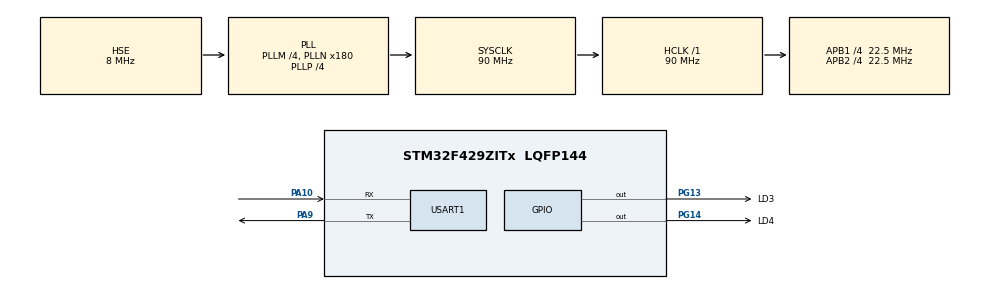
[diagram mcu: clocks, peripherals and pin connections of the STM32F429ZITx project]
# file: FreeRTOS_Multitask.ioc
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FREERTOS.Tasks01=defaultTask,24,128,StartDefaultTask,Default,NULL,Dynamic,NULL,NULL;myTask,24,128,StartMyTask,Default,NULL,Dynamic,NULL,NULL;myLowTask,8,128,StartLowTask,Default,NULL,Dynamic,NULL,NULL
Mcu.Family=STM32F4
Mcu.Name=STM32F429ZITx
Mcu.Package=LQFP144
NVIC.PriorityGroup=NVIC_PRIORITYGROUP_4
PA10.Mode=Asynchronous
PA10.Signal=USART1_RX
PA9.Mode=Asynchronous
PA9.Signal=USART1_TX
PG13.GPIO_Label=LD3
PG13.Signal=GPIO_Output
PG14.GPIO_Label=LD4
PG14.Signal=GPIO_Output
PH0/OSC_IN.Mode=HSE-External-Oscillator
PH0/OSC_IN.Signal=RCC_OSC_IN
PH1/OSC_OUT.Mode=HSE-External-Oscillator
PH1/OSC_OUT.Signal=RCC_OSC_OUT
ProjectManager.HeapSize=0x200
ProjectManager.StackSize=0x400
ProjectManager.TargetToolchain=STM32CubeIDE
RCC.48MHZClocksFreq_Value=90000000
RCC.AHBFreq_Value=90000000
RCC.APB1CLKDivider=RCC_HCLK_DIV4
RCC.APB1Freq_Value=22500000
RCC.APB1TimFreq_Value=45000000
RCC.APB2CLKDivider=RCC_HCLK_DIV4
RCC.APB2Freq_Value=22500000
RCC.APB2TimFreq_Value=45000000
RCC.CortexFreq_Value=90000000
RCC.HCLKFreq_Value=90000000
RCC.HSE_VALUE=8000000
RCC.HSI_VALUE=16000000
RCC.LSE_VALUE=32768
RCC.PLLM=4
RCC.PLLN=180
RCC.PLLP=RCC_PLLP_DIV4
RCC.PLLSourceVirtual=RCC_PLLSOURCE_HSE
RCC.SYSCLKFreq_VALUE=90000000
RCC.SYSCLKSource=RCC_SYSCLKSOURCE_PLLCLK
RCC.VCOOutputFreq_Value=360000000
TIM6.Period=99
TIM6.Prescaler=89
USART1.VirtualMode=VM_ASYNC
VP_FREERTOS_VS_CMSIS_V2.Mode=CMSIS_V2
VP_TIM6_VS_ClockSourceINT.Mode=Enable_Timer
board=custom

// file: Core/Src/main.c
/* USER CODE BEGIN Header */
/**
  ******************************************************************************
  * @file           : main.c
  * @brief          : Main program body
  ******************************************************************************
  * @attention
  *
  * Copyright (c) 2025 STMicroelectronics.
  * All rights reserved.
  *
  * This software is licensed under terms that can be found in the LICENSE file
  * in the root directory of this software component.
  * If no LICENSE file comes with this software, it is provided AS-IS.
  *
  ******************************************************************************
  */
/* USER CODE END Header */
#include "main.h"
#include "cmsis_os.h"

TIM_HandleTypeDef htim6;

UART_HandleTypeDef huart1;

/* Definitions for defaultTask */
osThreadId_t defaultTaskHandle;
const osThreadAttr_t defaultTask_attributes = {
  .name = "defaultTask",
  .stack_size = 128 * 4,
  .priority = (osPriority_t) osPriorityNormal,
};
/* Definitions for myTask */
osThreadId_t myTaskHandle;
const osThreadAttr_t myTask_attributes = {
  .name = "myTask",
  .stack_size = 128 * 4,
  .priority = (osPriority_t) osPriorityNormal,
};
/* Definitions for myLowTask */
osThreadId_t myLowTaskHandle;
const osThreadAttr_t myLowTask_attributes = {
  .name = "myLowTask",
  .stack_size = 128 * 4,
  .priority = (osPriority_t) osPriorityLow,
};

void SystemClock_Config(void);
static void MX_GPIO_Init(void);
static void MX_USART1_UART_Init(void);
static void MX_TIM6_Init(void);
void StartDefaultTask(void *argument);
void StartMyTask(void *argument);
void StartLowTask(void *argument);

int main(void)
{

  /* MCU Configuration--------------------------------------------------------*/

  /* Reset of all peripherals, Initializes the Flash interface and the Systick. */
  HAL_Init();

  /* Configure the system clock */
  SystemClock_Config();

  /* Initialize all configured peripherals */
  MX_GPIO_Init();
  MX_USART1_UART_Init();
  MX_TIM6_Init();

  /* Init scheduler */
  osKernelInitialize();

  /* Create the thread(s) */
  /* creation of defaultTask */
  defaultTaskHandle = osThreadNew(StartDefaultTask, NULL, &defaultTask_attributes);

  /* creation of myTask */
  myTaskHandle = osThreadNew(StartMyTask, NULL, &myTask_attributes);

  /* creation of myLowTask */
  myLowTaskHandle = osThreadNew(StartLowTask, NULL, &myLowTask_attributes);

  /* Start scheduler */
  osKernelStart();

  /* We should never get here as control is now taken by the scheduler */

  /* Infinite loop */
  while (1)
  {

  }
}

void SystemClock_Config(void)
{
  RCC_OscInitTypeDef RCC_OscInitStruct = {0};
  RCC_ClkInitTypeDef RCC_ClkInitStruct = {0};

  /** Configure the main internal regulator output voltage
  */
  __HAL_RCC_PWR_CLK_ENABLE();
  __HAL_PWR_VOLTAGESCALING_CONFIG(PWR_REGULATOR_VOLTAGE_SCALE3);

  /** Initializes the RCC Oscillators according to the specified parameters
  * in the RCC_OscInitTypeDef structure.
  */
  RCC_OscInitStruct.OscillatorType = RCC_OSCILLATORTYPE_HSE;
  RCC_OscInitStruct.HSEState = RCC_HSE_ON;
  RCC_OscInitStruct.PLL.PLLState = RCC_PLL_ON;
  RCC_OscInitStruct.PLL.PLLSource = RCC_PLLSOURCE_HSE;
  RCC_OscInitStruct.PLL.PLLM = 4;
  RCC_OscInitStruct.PLL.PLLN = 180;
  RCC_OscInitStruct.PLL.PLLP = RCC_PLLP_DIV4;
  RCC_OscInitStruct.PLL.PLLQ = 4;
  if (HAL_RCC_OscConfig(&RCC_OscInitStruct) != HAL_OK)
  {
    Error_Handler();
  }

  /** Initializes the CPU, AHB and APB buses clocks
  */
  RCC_ClkInitStruct.ClockType = RCC_CLOCKTYPE_HCLK|RCC_CLOCKTYPE_SYSCLK
                              |RCC_CLOCKTYPE_PCLK1|RCC_CLOCKTYPE_PCLK2;
  RCC_ClkInitStruct.SYSCLKSource = RCC_SYSCLKSOURCE_PLLCLK;
  RCC_ClkInitStruct.AHBCLKDivider = RCC_SYSCLK_DIV1;
  RCC_ClkInitStruct.APB1CLKDivider = RCC_HCLK_DIV4;
  RCC_ClkInitStruct.APB2CLKDivider = RCC_HCLK_DIV4;

  if (HAL_RCC_ClockConfig(&RCC_ClkInitStruct, FLASH_LATENCY_2) != HAL_OK)
  {
    Error_Handler();
  }
}

static void MX_TIM6_Init(void)
{

  TIM_MasterConfigTypeDef sMasterConfig = {0};

  htim6.Instance = TIM6;
  htim6.Init.Prescaler = 89;
  htim6.Init.CounterMode = TIM_COUNTERMODE_UP;
  htim6.Init.Period = 99;
  htim6.Init.AutoReloadPreload = TIM_AUTORELOAD_PRELOAD_DISABLE;
  if (HAL_TIM_Base_Init(&htim6) != HAL_OK)
  {
    Error_Handler();
  }
  sMasterConfig.MasterOutputTrigger = TIM_TRGO_RESET;
  sMasterConfig.MasterSlaveMode = TIM_MASTERSLAVEMODE_DISABLE;
  if (HAL_TIMEx_MasterConfigSynchronization(&htim6, &sMasterConfig) != HAL_OK)
  {
    Error_Handler();
  }

}

static void MX_USART1_UART_Init(void)
{

  huart1.Instance = USART1;
  huart1.Init.BaudRate = 115200;
  huart1.Init.WordLength = UART_WORDLENGTH_8B;
  huart1.Init.StopBits = UART_STOPBITS_1;
  huart1.Init.Parity = UART_PARITY_NONE;
  huart1.Init.Mode = UART_MODE_TX_RX;
  huart1.Init.HwFlowCtl = UART_HWCONTROL_NONE;
  huart1.Init.OverSampling = UART_OVERSAMPLING_16;
  if (HAL_UART_Init(&huart1) != HAL_OK)
  {
    Error_Handler();
  }

}

static void MX_GPIO_Init(void)
{
  GPIO_InitTypeDef GPIO_InitStruct = {0};

  /* GPIO Ports Clock Enable */
  __HAL_RCC_GPIOH_CLK_ENABLE();
  __HAL_RCC_GPIOA_CLK_ENABLE();
  __HAL_RCC_GPIOG_CLK_ENABLE();

  /*Configure GPIO pin Output Level */
  HAL_GPIO_WritePin(GPIOG, LD3_Pin|LD4_Pin, GPIO_PIN_RESET);

  /*Configure GPIO pins : LD3_Pin LD4_Pin */
  GPIO_InitStruct.Pin = LD3_Pin|LD4_Pin;
  GPIO_InitStruct.Mode = GPIO_MODE_OUTPUT_PP;
  GPIO_InitStruct.Pull = GPIO_NOPULL;
  GPIO_InitStruct.Speed = GPIO_SPEED_FREQ_LOW;
  HAL_GPIO_Init(GPIOG, &GPIO_InitStruct);

}

/* USER CODE BEGIN Header_StartDefaultTask */
/**
  * @brief  Hàm thực thi trong task mặc định của FreeRTOS, defaultTask thread.
  * @param  argument: Not used
  * @retval None
  */
/* USER CODE END Header_StartDefaultTask */
void StartDefaultTask(void *argument)
{
  /* USER CODE BEGIN 5 */
  /* Infinite loop */
  for(;;)
  {
	/// Tạm dừng 0.5s. Lưu ý: Bắt buộc phải có, cho dù thời gian đợi nhỏ
    osDelay(500);
    /// Đảo trạng thái Tắt/Bật đèn led LD3
    HAL_GPIO_TogglePin(LD3_GPIO_Port, LD3_Pin);
  }
  /* USER CODE END 5 */
}

/* USER CODE BEGIN Header_StartMyTask */
/**
* @brief Hàm thực thi bên trong Task mới, myTask thread.
* @param argument: Not used
* @retval None
*/
/* USER CODE END Header_StartMyTask */
void StartMyTask(void *argument)
{
  /* USER CODE BEGIN StartMyTask */
  /* Infinite loop */
  for(;;)
  {
	/// Tạm dừng 0.7s. Lưu ý: Bắt buộc phải có, cho dù thời gian đợi nhỏ
    //osDelay(700);   // Hàm delay none-blocking
	HAL_Delay(700);   // Hàm delay blocking, nên mới chiếm tài nguyên CPU, không để cho LowTask được thực thi
    /// Đảo trạng thái Tắt/Bật đèn led L4;
    HAL_GPIO_TogglePin(LD4_GPIO_Port, LD4_Pin);
    /// Gửi thông báo về máy tính qua UART1
    HAL_UART_Transmit(&huart1, "MyTask\n",7,10);
  }
  /* USER CODE END StartMyTask */
}

void StartLowTask(void *argument)
{
  /* USER CODE BEGIN StartLowTask */
  /* Infinite loop */
  for(;;)
  {
	/// Tạm dừng 0.7s. Lưu ý: Bắt buộc phải có, cho dù thời gian đợi nhỏ
	osDelay(700);
	/// Gửi thông báo về máy tính qua UART1
	HAL_UART_Transmit(&huart1, "LowTask\n",8,10);
  }
  /* USER CODE END StartLowTask */
}

void Error_Handler(void)
{
  __disable_irq();
  while (1)
  {
  }
}
